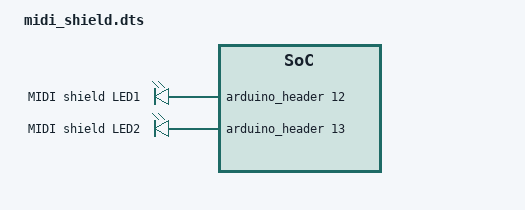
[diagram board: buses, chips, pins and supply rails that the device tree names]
/ {
    leds {
        compatible = "gpio-leds";
        midi_shield_led1: midi_shield_led1 {
            gpios = <&arduino_header 12 0>;
            label = "MIDI shield LED1";
        };
        midi_shield_led2: midi_shield_led2 {
            gpios = <&arduino_header 13 0>;
            label = "MIDI shield LED2";
        };
    };

    aliases {
        midiled1 = &midi_shield_led1;
        midiled2 = &midi_shield_led2;
        midiport = &arduino_serial;
    };
};
